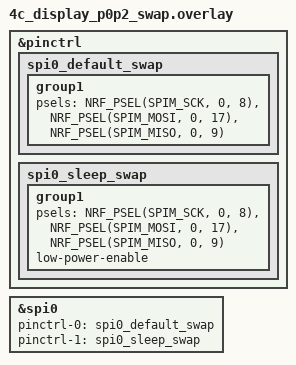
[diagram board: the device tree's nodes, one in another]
&pinctrl {
    spi0_default_swap: spi0_default_swap {
        group1 {
            psels = <NRF_PSEL(SPIM_SCK, 0, 8)>,
                    <NRF_PSEL(SPIM_MOSI, 0, 17)>,
                    <NRF_PSEL(SPIM_MISO, 0, 9)>;
        };
    };

    spi0_sleep_swap: spi0_sleep_swap {
        group1 {
            psels = <NRF_PSEL(SPIM_SCK, 0, 8)>,
                    <NRF_PSEL(SPIM_MOSI, 0, 17)>,
                    <NRF_PSEL(SPIM_MISO, 0, 9)>;
            low-power-enable;
        };
    };
};

&spi0 {
    pinctrl-0 = <&spi0_default_swap>;
    pinctrl-1 = <&spi0_sleep_swap>;
};
